VERSION ""

NS_ :

BS_:

BU_: ECU1

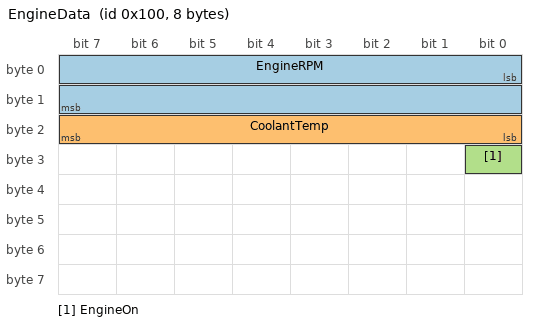
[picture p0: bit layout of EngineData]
BO_ 256 EngineData: 8 ECU1
 SG_ EngineRPM : 0|16@1+ (0.25,0) [0|16383.75] "rpm" Vector__XXX
 SG_ CoolantTemp : 16|8@1+ (1,-40) [-40|215] "C" Vector__XXX
 SG_ EngineOn : 24|1@1+ (1,0) [0|1] "" Vector__XXX

BO_ 512 VehicleSpeed: 4 ECU1
 SG_ Speed : 0|16@1+ (0.01,0) [0|655.35] "km/h" Vector__XXX
 SG_ GearPos : 16|4@1+ (1,0) [0|15] "" Vector__XXX
